# FX1 register map
Vendor: FTEL; File version: VP_FX1_V3.0_ISP_1.07
Registers are 32-bit, read-write, reset 0x0 unless marked. A register's access mark holds for its fields unless they carry their own. Offsets are from the block's base; [hi:lo] are bit positions; {n}, {i} and the like mark numbered series; 'fields as' and 'values as' point back to an identical list; <NAME> marks a mode.

## SYS_DMA — 8 kênh, stride 0x100, aperture register 0x1100, FIFO 32 byte, max transfer 1023 byte. Reset không có nguồn: null.
Base 0x10010000
{0x0+0x100*i} CH{i}_CMD_READ_ADDR reset not defined (i=0..7) — SYS_DMA kênh {i}, CMD_READ_ADDR; theo include/dma/fx1_dma_regs.h. Không dùng map PL330 cũ. [access=rw]
{0x4+0x100*i} CH{i}_CMD_WRITE_ADDR reset not defined (i=0..7) — SYS_DMA kênh {i}, CMD_WRITE_ADDR; theo include/dma/fx1_dma_regs.h. Không dùng map PL330 cũ. [access=rw]
{0x8+0x100*i} CH{i}_CMD_TRANSFER_SIZE reset not defined (i=0..7) — SYS_DMA kênh {i}, CMD_TRANSFER_SIZE; theo include/dma/fx1_dma_regs.h. Không dùng map PL330 cũ. [access=rw]
  [9:0] BYTES — [access=rw]
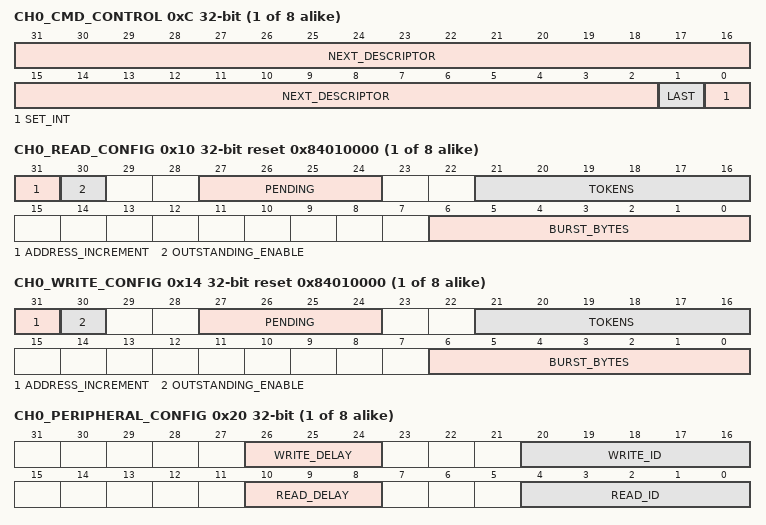
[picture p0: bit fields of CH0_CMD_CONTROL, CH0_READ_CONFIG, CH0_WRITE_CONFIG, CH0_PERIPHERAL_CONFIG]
{0xC+0x100*i} CH{i}_CMD_CONTROL reset not defined (i=0..7) — SYS_DMA kênh {i}, CMD_CONTROL; theo include/dma/fx1_dma_regs.h. Không dùng map PL330 cũ. [access=rw]
  [31:2] NEXT_DESCRIPTOR — [access=rw]
  [1] LAST — [access=rw]
  [0] SET_INT — [access=rw]
{0x10+0x100*i} CH{i}_READ_CONFIG reset 0x84010000 (i=0..7) — SYS_DMA kênh {i}, READ_CONFIG; theo include/dma/fx1_dma_regs.h. Không dùng map PL330 cũ. [access=rw]
  [31] ADDRESS_INCREMENT — [access=rw]
  [30] OUTSTANDING_ENABLE — [access=rw]
  [27:24] PENDING — [access=rw]
  [21:16] TOKENS — [access=rw]
  [6:0] BURST_BYTES — [access=rw]
{0x14+0x100*i} CH{i}_WRITE_CONFIG reset 0x84010000 (i=0..7) — SYS_DMA kênh {i}, WRITE_CONFIG; theo include/dma/fx1_dma_regs.h. Không dùng map PL330 cũ. [access=rw]
  fields as CH0_READ_CONFIG
{0x18+0x100*i} CH{i}_MODE_CONFIG reset not defined (i=0..7) — SYS_DMA kênh {i}, MODE_CONFIG; theo include/dma/fx1_dma_regs.h. Không dùng map PL330 cũ. [access=rw]
  [29:28] BYTE_SWAP — [access=rw]
{0x1C+0x100*i} CH{i}_SCHEDULE_CONFIG reset not defined (i=0..7) — SYS_DMA kênh {i}, SCHEDULE_CONFIG; theo include/dma/fx1_dma_regs.h. Không dùng map PL330 cũ. [access=rw]
{0x20+0x100*i} CH{i}_PERIPHERAL_CONFIG reset not defined (i=0..7) — SYS_DMA kênh {i}, PERIPHERAL_CONFIG; theo include/dma/fx1_dma_regs.h. Không dùng map PL330 cũ. [access=rw]
  [26:24] WRITE_DELAY — [access=rw]
  [20:16] WRITE_ID — [access=rw]
  [10:8] READ_DELAY — [access=rw]
  [4:0] READ_ID — [access=rw]
{0x24+0x100*i} CH{i}_AXI_ATTR_REG reset not defined (i=0..7) — SYS_DMA kênh {i}, AXI_ATTR_REG; theo include/dma/fx1_dma_regs.h. Không dùng map PL330 cũ. [access=rw]
{0x2C+0x100*i} CH{i}_RESTRICTION_STATUS ro reset not defined (i=0..7) — SYS_DMA kênh {i}, RESTRICTION_STATUS; theo include/dma/fx1_dma_regs.h. Không dùng map PL330 cũ. [access=ro]
{0x30+0x100*i} CH{i}_READ_OFFSET_STATUS ro reset not defined (i=0..7) — SYS_DMA kênh {i}, READ_OFFSET_STATUS; theo include/dma/fx1_dma_regs.h. Không dùng map PL330 cũ. [access=ro]
{0x34+0x100*i} CH{i}_WRITE_OFFSET_STATUS ro reset not defined (i=0..7) — SYS_DMA kênh {i}, WRITE_OFFSET_STATUS; theo include/dma/fx1_dma_regs.h. Không dùng map PL330 cũ. [access=ro]
{0x38+0x100*i} CH{i}_FIFO_STATUS ro reset not defined (i=0..7) — SYS_DMA kênh {i}, FIFO_STATUS; theo include/dma/fx1_dma_regs.h. Không dùng map PL330 cũ. [access=ro]
{0x3C+0x100*i} CH{i}_OUTSTANDING_STATUS ro reset not defined (i=0..7) — SYS_DMA kênh {i}, OUTSTANDING_STATUS; theo include/dma/fx1_dma_regs.h. Không dùng map PL330 cũ. [access=ro]
{0x40+0x100*i} CH{i}_ENABLE reset not defined (i=0..7) — SYS_DMA kênh {i}, ENABLE; theo include/dma/fx1_dma_regs.h. Không dùng map PL330 cũ. [access=rw]
{0x44+0x100*i} CH{i}_START wo reset not defined (i=0..7) — SYS_DMA kênh {i}, START; theo include/dma/fx1_dma_regs.h. Không dùng map PL330 cũ. [access=wo]
{0x48+0x100*i} CH{i}_ACTIVE_STATUS ro reset not defined (i=0..7) — SYS_DMA kênh {i}, ACTIVE_STATUS; theo include/dma/fx1_dma_regs.h. Không dùng map PL330 cũ. [access=ro]
{0x50+0x100*i} CH{i}_TRANSFER_COUNT ro reset not defined (i=0..7) — SYS_DMA kênh {i}, TRANSFER_COUNT; theo include/dma/fx1_dma_regs.h. Không dùng map PL330 cũ. [access=ro]
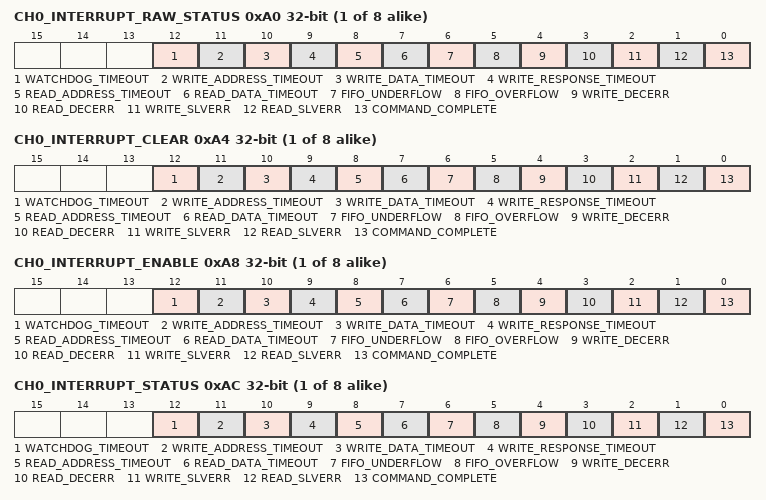
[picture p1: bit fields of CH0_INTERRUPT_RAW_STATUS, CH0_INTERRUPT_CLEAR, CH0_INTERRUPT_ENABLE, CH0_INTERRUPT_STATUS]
{0xA0+0x100*i} CH{i}_INTERRUPT_RAW_STATUS ro reset not defined (i=0..7) — SYS_DMA kênh {i}, INTERRUPT_RAW_STATUS; theo include/dma/fx1_dma_regs.h. Không dùng map PL330 cũ. [access=ro]
  [12] WATCHDOG_TIMEOUT — [access=ro]
  [11] WRITE_ADDRESS_TIMEOUT — [access=ro]
  [10] WRITE_DATA_TIMEOUT — [access=ro]
  [9] WRITE_RESPONSE_TIMEOUT — [access=ro]
  [8] READ_ADDRESS_TIMEOUT — [access=ro]
  [7] READ_DATA_TIMEOUT — [access=ro]
  [6] FIFO_UNDERFLOW — [access=ro]
  [5] FIFO_OVERFLOW — [access=ro]
  [4] WRITE_DECERR — [access=ro]
  [3] READ_DECERR — [access=ro]
  [2] WRITE_SLVERR — [access=ro]
  [1] READ_SLVERR — [access=ro]
  [0] COMMAND_COMPLETE — [access=ro]
{0xA4+0x100*i} CH{i}_INTERRUPT_CLEAR reset not defined write-1-clears (i=0..7) — SYS_DMA kênh {i}, INTERRUPT_CLEAR; theo include/dma/fx1_dma_regs.h. Không dùng map PL330 cũ. [access=w1c]
  [12] WATCHDOG_TIMEOUT write-1-clears — [access=w1c]
  [11] WRITE_ADDRESS_TIMEOUT write-1-clears — [access=w1c]
  [10] WRITE_DATA_TIMEOUT write-1-clears — [access=w1c]
  [9] WRITE_RESPONSE_TIMEOUT write-1-clears — [access=w1c]
  [8] READ_ADDRESS_TIMEOUT write-1-clears — [access=w1c]
  [7] READ_DATA_TIMEOUT write-1-clears — [access=w1c]
  [6] FIFO_UNDERFLOW write-1-clears — [access=w1c]
  [5] FIFO_OVERFLOW write-1-clears — [access=w1c]
  [4] WRITE_DECERR write-1-clears — [access=w1c]
  [3] READ_DECERR write-1-clears — [access=w1c]
  [2] WRITE_SLVERR write-1-clears — [access=w1c]
  [1] READ_SLVERR write-1-clears — [access=w1c]
  [0] COMMAND_COMPLETE write-1-clears — [access=w1c]
{0xA8+0x100*i} CH{i}_INTERRUPT_ENABLE reset not defined (i=0..7) — SYS_DMA kênh {i}, INTERRUPT_ENABLE; theo include/dma/fx1_dma_regs.h. Không dùng map PL330 cũ. [access=rw]
  [12] WATCHDOG_TIMEOUT — [access=rw]
  [11] WRITE_ADDRESS_TIMEOUT — [access=rw]
  [10] WRITE_DATA_TIMEOUT — [access=rw]
  [9] WRITE_RESPONSE_TIMEOUT — [access=rw]
  [8] READ_ADDRESS_TIMEOUT — [access=rw]
  [7] READ_DATA_TIMEOUT — [access=rw]
  [6] FIFO_UNDERFLOW — [access=rw]
  [5] FIFO_OVERFLOW — [access=rw]
  [4] WRITE_DECERR — [access=rw]
  [3] READ_DECERR — [access=rw]
  [2] WRITE_SLVERR — [access=rw]
  [1] READ_SLVERR — [access=rw]
  [0] COMMAND_COMPLETE — [access=rw]
{0xAC+0x100*i} CH{i}_INTERRUPT_STATUS ro reset not defined (i=0..7) — SYS_DMA kênh {i}, INTERRUPT_STATUS; theo include/dma/fx1_dma_regs.h. Không dùng map PL330 cũ. [access=ro]
  fields as CH0_INTERRUPT_RAW_STATUS
0x1000 CORE_STATUS ro reset not defined — Theo include/dma/fx1_dma_regs.h. [access=ro]
0x1030 CORE_JOINT_CONFIG reset not defined — Theo include/dma/fx1_dma_regs.h. [access=rw]
0x1038 CORE_PRIORITY_CONFIG reset not defined — Theo include/dma/fx1_dma_regs.h. [access=rw]
0x1040 CORE_CLOCK_DIVIDER reset not defined — Theo include/dma/fx1_dma_regs.h. [access=rw]
0x1048 CORE_CHANNEL_START wo reset not defined — Theo include/dma/fx1_dma_regs.h. [access=wo]
0x10D0 CORE_IDLE_STATUS ro reset not defined — Theo include/dma/fx1_dma_regs.h. [access=ro]
0x10E0 DESIGN_CAPABILITY_STATUS ro reset not defined — Theo include/dma/fx1_dma_regs.h. [access=ro]
0x10F0 CORE_CAPABILITY_STATUS0 ro reset 0xA602258 — Theo include/dma/fx1_dma_regs.h. [access=ro]
0x10F4 CORE_CAPABILITY_STATUS1 ro reset not defined — Theo include/dma/fx1_dma_regs.h. [access=ro]

## UART — PL011-like VP; IRQ 1. FE/PE/BE không được kích thích; không có modem IRQ. Reset null: nguồn không xác nhận.
Base 0x10000000
0x00 DR reset not defined read-modifies — Đọc pop RX FIFO, ghi push TX FIFO. Không đọc bằng debugger khi đang nhận dữ liệu. [access=rw]
0x04 RSR_ECR reset not defined — Đọc trạng thái lỗi; ghi để clear lỗi. Khác với register RW thông thường. [access=rw]
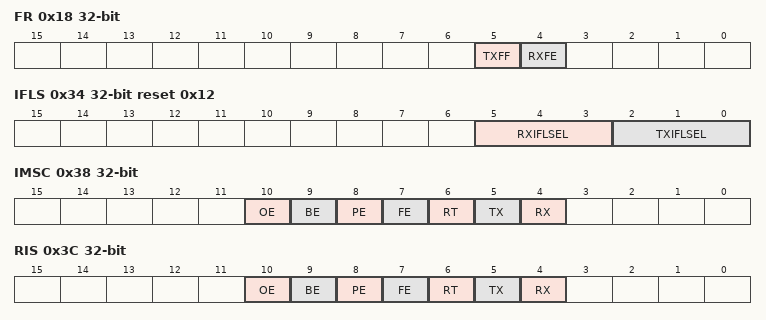
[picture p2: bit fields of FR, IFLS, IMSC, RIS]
0x18 FR ro reset not defined — Trạng thái FIFO; RXFE bit 4, TXFF bit 5 theo BSP. [access=ro]
  [5] TXFF — [access=ro]
  [4] RXFE — [access=ro]
0x24 IBRD reset not defined — Integer baud divisor. [access=rw]
0x28 FBRD reset not defined — Fractional baud divisor. [access=rw]
0x2C LCR_H reset not defined — Cấu hình line; FIFO-disable mode không được mô phỏng. [access=rw]
0x30 CR reset not defined — UART control. [access=rw]
0x34 IFLS reset 0x12 — Ngưỡng FIFO 16 phần tử. [access=rw]
  [5:3] RXIFLSEL — [access=rw]
  [2:0] TXIFLSEL — [access=rw]
0x38 IMSC reset not defined — Interrupt mask. [access=rw]
  [10] OE — [access=rw]
  [9] BE — [access=rw]
  [8] PE — [access=rw]
  [7] FE — [access=rw]
  [6] RT — [access=rw]
  [5] TX — [access=rw]
  [4] RX — [access=rw]
0x3C RIS ro reset not defined — Raw interrupt status. [access=ro]
  [10] OE — [access=ro]
  [9] BE — [access=ro]
  [8] PE — [access=ro]
  [7] FE — [access=ro]
  [6] RT — [access=ro]
  [5] TX — [access=ro]
  [4] RX — [access=ro]
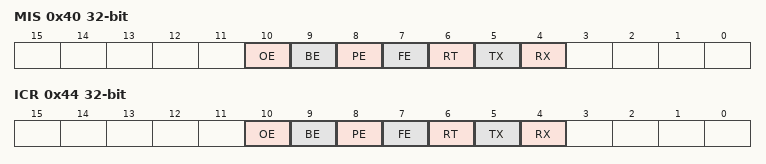
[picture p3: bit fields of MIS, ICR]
0x40 MIS ro reset not defined — Masked interrupt status; MIS khác 0 tạo IRQ. [access=ro]
  fields as RIS
0x44 ICR reset not defined write-1-clears — Ghi 1 clear raw interrupt tương ứng. [access=w1c]
  [10] OE write-1-clears — [access=w1c]
  [9] BE write-1-clears — [access=w1c]
  [8] PE write-1-clears — [access=w1c]
  [7] FE write-1-clears — [access=w1c]
  [6] RT write-1-clears — [access=w1c]
  [5] TX write-1-clears — [access=w1c]
  [4] RX write-1-clears — [access=w1c]

## SIM_CTRL — CHỈ VP, không dùng cho silicon.
Base 0x10020000
0x00 FINISH wo reset not defined — Ghi 0x5555 PASS; ghi (code << 16) | 0x3333 FAIL. [access=wo]
0x04 IRQ reset not defined — Bit i điều khiển đường test i, nối PLIC source FX1_SIM_CTRL_IRQ_FIRST_SOURCE + i (10..11). [access=rw]
  [1:0] TEST_LINES — [access=rw]

## I2C0 — Phần Host dùng trong drivers/camera/fx1_i2c.c, IRQ 9. Chưa khai toàn bộ register của IP I2C; không thay map bằng OpenTitan upstream.
Base 0x10030000
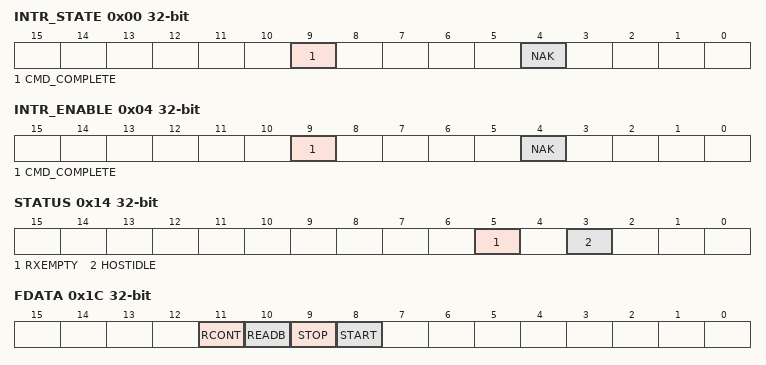
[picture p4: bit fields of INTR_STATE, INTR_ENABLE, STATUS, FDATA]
0x00 INTR_STATE reset not defined write-1-clears — Trạng thái IRQ, ghi 1 clear. [access=w1c]
  [9] CMD_COMPLETE write-1-clears — [access=w1c]
  [4] NAK write-1-clears — [access=w1c]
0x04 INTR_ENABLE reset not defined — Enable IRQ. [access=rw]
  [9] CMD_COMPLETE — [access=rw]
  [4] NAK — [access=rw]
0x10 CTRL reset not defined — Điều khiển host. [access=rw]
  [0] ENABLEHOST — [access=rw]
0x14 STATUS ro reset not defined — Host và RX FIFO. [access=ro]
  [5] RXEMPTY — [access=ro]
  [3] HOSTIDLE — [access=ro]
0x18 RDATA ro reset not defined read-modifies — Đọc pop RX FIFO. [access=ro]
0x1C FDATA wo reset not defined — Ghi lệnh vào FMT FIFO. [access=wo]
  [11] RCONT — [access=wo]
  [10] READB — [access=wo]
  [9] STOP — [access=wo]
  [8] START — [access=wo]
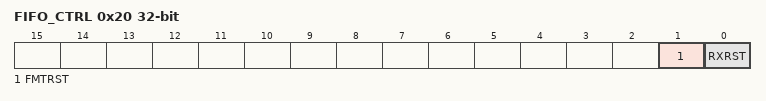
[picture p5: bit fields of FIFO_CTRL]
0x20 FIFO_CTRL reset not defined — Lệnh reset FIFO; xác nhận thêm hành vi readback/self-clear trong IP. [access=rw]
  [1] FMTRST — [access=rw]
  [0] RXRST — [access=rw]
